# PIC32MZ2025DAB288 device description
Architecture: MIPS; Family: PIC32MZDA; Series: PIC32MZ
Registers are 32-bit, read-write, no defined reset value unless marked. A register's access mark holds for its fields unless they carry their own. Offsets are from the block's base; [hi:lo] are bit positions.

## RCON
Instances: RCON 0x1f801200 in periph_pb1_std
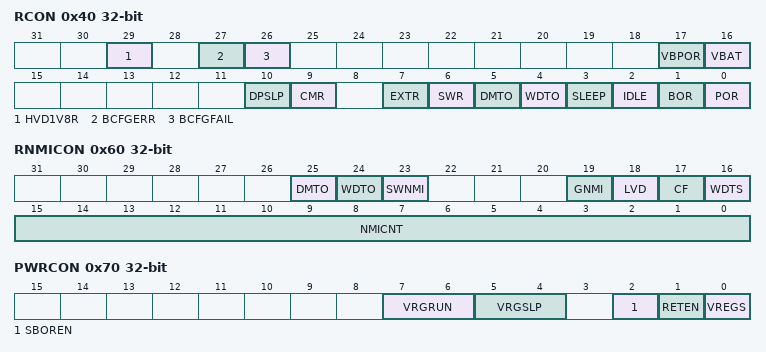
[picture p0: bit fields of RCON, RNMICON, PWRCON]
0x40 RCON — Reset Control Register
  [29] HVD1V8R — VDDR1V8 (DDR2) High Voltage Detect Flag bit
    1=A high voltage condition on the VDDR1V8 voltage has occurred; 0=A high voltage condition on the VDDR1V8 voltage has not occurred
  [27] BCFGERR — Primary Configuration Registers Error Flag bit
    1=An error occurred during a read of the primary configuration registers; 0=No error occurred during a read of the primary configuration registers
  [26] BCFGFAIL — Primary/Secondary Configuration Registers Error Flag bit
    1=An error occurred during a read of the primary and alternate configuration registers; 0=No error occurred during a read of the primary and alternate configuration registers
  [17] VBPOR — VBPOR Mode Flag bit
    1=POR (A VBAT domain POR has occurred); 0=NOPOR (A VBAT domain POR has not occurred)
  [16] VBAT — VBAT Mode Flag bit
    1=POR (A POR exit from VBAT has occurred); 0=NOPOR (A POR exit from VBAT has not occurred)
  [10] DPSLP — Deep Sleep Mode Flag bit
    1=SLEEP (Deep Sleep mode has occurred); 0=NOSLEEP (Deep Sleep mode has not occurred)
  [9] CMR — Configuration Mismatch Reset Flag bit
    1=A Configuration Mismatch Reset has occurred; 0=A Configuration Mismatch Reset has not occurred
  [7] EXTR — External Reset (MCLR) Pin Flag bit
    1=Master Clear (pin) Reset has occurred; 0=Master Clear (pin) Reset has not occurred
  [6] SWR — Software Reset Flag bit
    1=Software Reset was executed; 0=Software Reset was not executed
  [5] DMTO — Deadman Timer Time-out Flag bit
    1=A DMT time-out has occurred; 0=A DMT time-out has not occurred
  [4] WDTO — Watchdog Timer Time-out Flag bit
    1=WDT Time-out has occurred; 0=WDT Time-out has not occurred
  [3] SLEEP — Wake From Sleep Flag bit
    1=Device was in Sleep mode; 0=Device was not in Sleep mode
  [2] IDLE — Wake From Idle Flag bit
    1=Device was in Idle mode; 0=Device was not in Idle mode
  [1] BOR — Brown-out Reset Flag bit
    1=Brown-out Reset has occurred; 0=Brown-out Reset has not occurred
  [0] POR — Power-on Reset Flag bit
    1=Power-on Reset has occurred; 0=Power-on Reset has not occurred
0x50 RSWRST wo — Software Reset Register
  [0] SWRST — Software Reset Trigger bit
    1=Enable software Reset event; 0=No effect
0x60 RNMICON — Non-maskable Interrupt (NMI) Control Register
  [25] DMTO — Deadman Timer Time-out Flag bit
    1=DMT time-out has occurred and caused a NMI; 0=DMT time-out has not occurred
  [24] WDTO — Watchdog Timer Time-Out Flag bit
    1=WDT time-out has occurred and caused a NMI; 0=WDT time-out has not occurred
  [23] SWNMI — Software NMI Trigger
    1=An NMI will be generated; 0=An NMI will not be generated
  [19] GNMI — General NMI bit
    1=A general NMI event has been detected or a user-initiated NMI event has occurred; 0=A general NMI event has not been detected
  [18] LVD
  [17] CF — Clock Fail Detect bit
    1=FSCM has detected clock failure and caused an NMI; 0=FSCM has not detected clock failure
  [16] WDTS — Watchdog Timer Time-out in Sleep Mode Flag bit
    1=WDT time-out has occurred during Sleep mode and caused a wake-up from sleep; 0=WDT time-out has not occurred during Sleep mode
  [15:0] NMICNT — NMI Reset Counter Value bits
    0xffff=65535 SYSCLK cycles before a device Reset occurs; 1=1 SYSCLK cycle before a device Reset occurs; 0=No delay between NMI assertion and device Reset event
0x70 PWRCON — Power Control Register
  [7:6] VRGRUN
  [5:4] VRGSLP
  [2] SBOREN
  [1] RETEN
  [0] VREGS — Voltage Regulator Stand-by Enable bit
    1=Voltage regulator will remain active during Sleep; 0=Voltage regulator will go to Stand-by mode during Sleep

## Notices in the file
Copyright (c) 2017 Microchip Technology Inc.
SPDX-License-Identifier: Apache-2.0
Licensed under the Apache License, Version 2.0 (the "License");
you may not use this file except in compliance with the License.
You may obtain a copy of the License at
http://www.apache.org/licenses/LICENSE-2.0
Unless required by applicable law or agreed to in writing, software
distributed under the License is distributed on an "AS IS" BASIS,
WITHOUT WARRANTIES OR CONDITIONS OF ANY KIND, either express or implied.
See the License for the specific language governing permissions and
limitations under the License.
